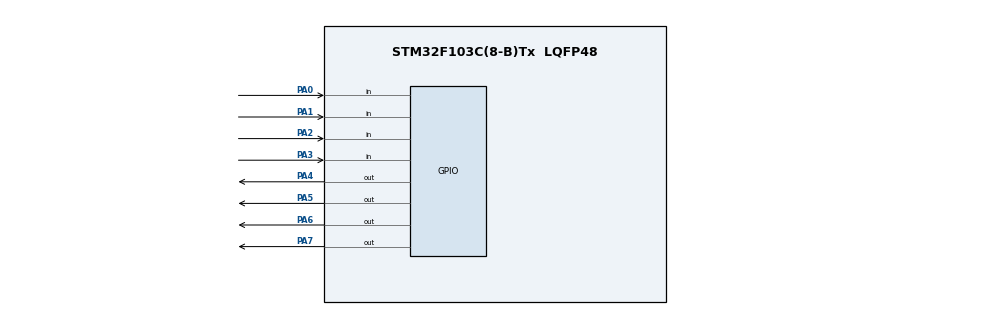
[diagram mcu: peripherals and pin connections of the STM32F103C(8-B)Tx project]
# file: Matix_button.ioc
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Mcu.Family=STM32F1
Mcu.Name=STM32F103C(8-B)Tx
Mcu.Package=LQFP48
NVIC.PriorityGroup=NVIC_PRIORITYGROUP_4
NVIC.TIM2_IRQn=true\:10\:0\:true\:false\:true\:true\:true
PA0-WKUP.GPIO_PuPd=GPIO_PULLUP
PA0-WKUP.Signal=GPIO_Input
PA1.GPIO_PuPd=GPIO_PULLUP
PA1.Signal=GPIO_Input
PA13.Mode=Serial_Wire
PA13.Signal=SYS_JTMS-SWDIO
PA14.Mode=Serial_Wire
PA14.Signal=SYS_JTCK-SWCLK
PA2.GPIO_PuPd=GPIO_PULLUP
PA2.Signal=GPIO_Input
PA3.GPIO_PuPd=GPIO_PULLUP
PA3.Signal=GPIO_Input
PA4.GPIO_Speed=GPIO_SPEED_FREQ_MEDIUM
PA4.PinState=GPIO_PIN_SET
PA4.Signal=GPIO_Output
PA5.GPIO_Speed=GPIO_SPEED_FREQ_MEDIUM
PA5.PinState=GPIO_PIN_SET
PA5.Signal=GPIO_Output
PA6.GPIO_Speed=GPIO_SPEED_FREQ_MEDIUM
PA6.PinState=GPIO_PIN_SET
PA6.Signal=GPIO_Output
PA7.GPIO_Speed=GPIO_SPEED_FREQ_MEDIUM
PA7.PinState=GPIO_PIN_SET
PA7.Signal=GPIO_Output
PC14-OSC32_IN.Mode=LSE-External-Oscillator
PC14-OSC32_IN.Signal=RCC_OSC32_IN
PC15-OSC32_OUT.Mode=LSE-External-Oscillator
PC15-OSC32_OUT.Signal=RCC_OSC32_OUT
PD0-OSC_IN.Mode=HSE-External-Oscillator
PD0-OSC_IN.Signal=RCC_OSC_IN
PD1-OSC_OUT.Mode=HSE-External-Oscillator
PD1-OSC_OUT.Signal=RCC_OSC_OUT
ProjectManager.HeapSize=0x200
ProjectManager.StackSize=0x400
ProjectManager.TargetToolchain=MDK-ARM V5.27
RCC.APB1Freq_Value=8000000
RCC.APB2Freq_Value=8000000
TIM2.AutoReloadPreload=TIM_AUTORELOAD_PRELOAD_ENABLE
TIM2.Period=1000
TIM2.Prescaler=7999
VP_TIM2_VS_ClockSourceINT.Mode=Internal
board=custom

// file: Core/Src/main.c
/* USER CODE BEGIN Header */
/**
  ******************************************************************************
  * @file           : main.c
  * @brief          : Main program body
  ******************************************************************************
  * @attention
  *
  * <h2><center>&copy; Copyright (c) 2021 STMicroelectronics.
  * All rights reserved.</center></h2>
  *
  * This software component is licensed by ST under BSD 3-Clause license,
  * the "License"; You may not use this file except in compliance with the
  * License. You may obtain a copy of the License at:
  *                        opensource.org/licenses/BSD-3-Clause
  *
  ******************************************************************************
  */
/* USER CODE END Header */
#include "main.h"
#include "tim.h"
#include "gpio.h"

/* USER CODE BEGIN Includes */
#include "matrix_button.h"
/* USER CODE END Includes */

/* USER CODE BEGIN PV */
volatile float g_u8Test = 0;
/* USER CODE END PV */

void SystemClock_Config(void);

int main(void)
{

  /* MCU Configuration--------------------------------------------------------*/

  /* Reset of all peripherals, Initializes the Flash interface and the Systick. */
  HAL_Init();

  /* Configure the system clock */
  SystemClock_Config();

  /* Initialize all configured peripherals */
  MX_GPIO_Init();
  MX_TIM2_Init();
  /* USER CODE BEGIN 2 */
	HAL_TIM_Base_Start_IT(&htim2);
  /* USER CODE END 2 */

  /* Infinite loop */
  while (1)
  {

    /* USER CODE BEGIN 3 */
		if(g_u8Test != NOT_BUTTON){
		}
		HAL_Delay(50u);

  }
  /* USER CODE END 3 */
}

void SystemClock_Config(void)
{
  RCC_OscInitTypeDef RCC_OscInitStruct = {0};
  RCC_ClkInitTypeDef RCC_ClkInitStruct = {0};

  /** Initializes the RCC Oscillators according to the specified parameters
  * in the RCC_OscInitTypeDef structure.
  */
  RCC_OscInitStruct.OscillatorType = RCC_OSCILLATORTYPE_HSI;
  RCC_OscInitStruct.HSIState = RCC_HSI_ON;
  RCC_OscInitStruct.HSICalibrationValue = RCC_HSICALIBRATION_DEFAULT;
  RCC_OscInitStruct.PLL.PLLState = RCC_PLL_NONE;
  if (HAL_RCC_OscConfig(&RCC_OscInitStruct) != HAL_OK)
  {
    Error_Handler();
  }
  /** Initializes the CPU, AHB and APB buses clocks
  */
  RCC_ClkInitStruct.ClockType = RCC_CLOCKTYPE_HCLK|RCC_CLOCKTYPE_SYSCLK
                              |RCC_CLOCKTYPE_PCLK1|RCC_CLOCKTYPE_PCLK2;
  RCC_ClkInitStruct.SYSCLKSource = RCC_SYSCLKSOURCE_HSI;
  RCC_ClkInitStruct.AHBCLKDivider = RCC_SYSCLK_DIV1;
  RCC_ClkInitStruct.APB1CLKDivider = RCC_HCLK_DIV1;
  RCC_ClkInitStruct.APB2CLKDivider = RCC_HCLK_DIV1;

  if (HAL_RCC_ClockConfig(&RCC_ClkInitStruct, FLASH_LATENCY_0) != HAL_OK)
  {
    Error_Handler();
  }
}

/* USER CODE BEGIN 4 */
void HAL_TIM_PeriodElapsedCallback(TIM_HandleTypeDef *htim)
{
  /* Prevent unused argument(s) compilation warning */
  UNUSED(htim);
	static uint8_t u8MatrixButton_count = 0u;
	u8MatrixButton_count++;
	if(u8MatrixButton_count >= 3){
		u8MatrixButton_count = 0u;
		g_u8Test = (float)buttonMatrix_scan_v2();
	}
}
/* USER CODE END 4 */

void Error_Handler(void)
{
  __disable_irq();
  while (1)
  {
  }
}

/************************ (C) COPYRIGHT STMicroelectronics *****END OF FILE****/
